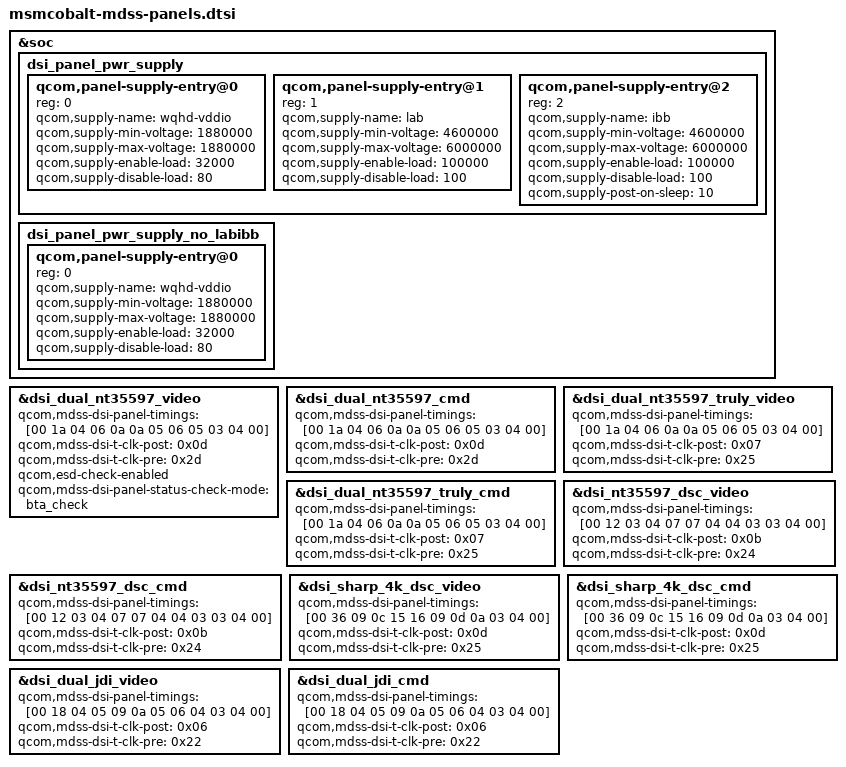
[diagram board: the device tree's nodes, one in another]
/* Copyright (c) 2016, The Linux Foundation. All rights reserved.
 *
 * This program is free software; you can redistribute it and/or modify
 * it under the terms of the GNU General Public License version 2 and
 * only version 2 as published by the Free Software Foundation.
 *
 * This program is distributed in the hope that it will be useful,
 * but WITHOUT ANY WARRANTY; without even the implied warranty of
 * MERCHANTABILITY or FITNESS FOR A PARTICULAR PURPOSE.  See the
 * GNU General Public License for more details.
 */

#include "dsi-panel-sim-video.dtsi"
#include "dsi-panel-sim-dualmipi-video.dtsi"
#include "dsi-panel-nt35597-dualmipi-wqxga-video.dtsi"
#include "dsi-panel-nt35597-dualmipi-wqxga-cmd.dtsi"
#include "dsi-panel-nt35597-truly-dualmipi-wqxga-video.dtsi"
#include "dsi-panel-nt35597-truly-dualmipi-wqxga-cmd.dtsi"
#include "dsi-panel-nt35597-dsc-wqxga-video.dtsi"
#include "dsi-panel-nt35597-dsc-wqxga-cmd.dtsi"
#include "dsi-panel-sharp-dsc-4k-video.dtsi"
#include "dsi-panel-sharp-dsc-4k-cmd.dtsi"
#include "dsi-panel-jdi-dualmipi-video.dtsi"
#include "dsi-panel-jdi-dualmipi-cmd.dtsi"

&soc {
	dsi_panel_pwr_supply: dsi_panel_pwr_supply {
		#address-cells = <1>;
		#size-cells = <0>;

		qcom,panel-supply-entry@0 {
			reg = <0>;
			qcom,supply-name = "wqhd-vddio";
			qcom,supply-min-voltage = <1880000>;
			qcom,supply-max-voltage = <1880000>;
			qcom,supply-enable-load = <32000>;
			qcom,supply-disable-load = <80>;
		};

		qcom,panel-supply-entry@1 {
			reg = <1>;
			qcom,supply-name = "lab";
			qcom,supply-min-voltage = <4600000>;
			qcom,supply-max-voltage = <6000000>;
			qcom,supply-enable-load = <100000>;
			qcom,supply-disable-load = <100>;
		};

		qcom,panel-supply-entry@2 {
			reg = <2>;
			qcom,supply-name = "ibb";
			qcom,supply-min-voltage = <4600000>;
			qcom,supply-max-voltage = <6000000>;
			qcom,supply-enable-load = <100000>;
			qcom,supply-disable-load = <100>;
			qcom,supply-post-on-sleep = <10>;
		};
	};
};

&soc {
	dsi_panel_pwr_supply_no_labibb: dsi_panel_pwr_supply_no_labibb {
		#address-cells = <1>;
		#size-cells = <0>;

		qcom,panel-supply-entry@0 {
			reg = <0>;
			qcom,supply-name = "wqhd-vddio";
			qcom,supply-min-voltage = <1880000>;
			qcom,supply-max-voltage = <1880000>;
			qcom,supply-enable-load = <32000>;
			qcom,supply-disable-load = <80>;
		};
	};
};

&dsi_dual_nt35597_video {
	qcom,mdss-dsi-panel-timings = [00 1a 04 06 0a 0a 05 06 05 03 04 00];
	qcom,mdss-dsi-t-clk-post = <0x0d>;
	qcom,mdss-dsi-t-clk-pre = <0x2d>;
	qcom,esd-check-enabled;
	qcom,mdss-dsi-panel-status-check-mode = "bta_check";
};

&dsi_dual_nt35597_cmd {
	qcom,mdss-dsi-panel-timings = [00 1a 04 06 0a 0a 05 06 05 03 04 00];
	qcom,mdss-dsi-t-clk-post = <0x0d>;
	qcom,mdss-dsi-t-clk-pre = <0x2d>;
};

&dsi_dual_nt35597_truly_video {
	qcom,mdss-dsi-panel-timings = [00 1a 04 06 0a 0a 05 06 05 03 04 00];
	qcom,mdss-dsi-t-clk-post = <0x07>;
	qcom,mdss-dsi-t-clk-pre = <0x25>;
};

&dsi_dual_nt35597_truly_cmd {
	qcom,mdss-dsi-panel-timings = [00 1a 04 06 0a 0a 05 06 05 03 04 00];
	qcom,mdss-dsi-t-clk-post = <0x07>;
	qcom,mdss-dsi-t-clk-pre = <0x25>;
};

&dsi_nt35597_dsc_video {
	qcom,mdss-dsi-panel-timings = [00 12 03 04 07 07 04 04 03 03 04 00];
	qcom,mdss-dsi-t-clk-post = <0x0b>;
	qcom,mdss-dsi-t-clk-pre = <0x24>;
};

&dsi_nt35597_dsc_cmd {
	qcom,mdss-dsi-panel-timings = [00 12 03 04 07 07 04 04 03 03 04 00];
	qcom,mdss-dsi-t-clk-post = <0x0b>;
	qcom,mdss-dsi-t-clk-pre = <0x24>;
};

&dsi_sharp_4k_dsc_video {
	qcom,mdss-dsi-panel-timings = [00 36 09 0c 15 16 09 0d 0a 03 04 00];
	qcom,mdss-dsi-t-clk-post = <0x0d>;
	qcom,mdss-dsi-t-clk-pre = <0x25>;
};

&dsi_sharp_4k_dsc_cmd {
	qcom,mdss-dsi-panel-timings = [00 36 09 0c 15 16 09 0d 0a 03 04 00];
	qcom,mdss-dsi-t-clk-post = <0x0d>;
	qcom,mdss-dsi-t-clk-pre = <0x25>;
};

&dsi_dual_jdi_video {
	qcom,mdss-dsi-panel-timings = [00 18 04 05 09 0a 05 06 04 03 04 00];
	qcom,mdss-dsi-t-clk-post = <0x06>;
	qcom,mdss-dsi-t-clk-pre = <0x22>;
};

&dsi_dual_jdi_cmd {
	qcom,mdss-dsi-panel-timings = [00 18 04 05 09 0a 05 06 04 03 04 00];
	qcom,mdss-dsi-t-clk-post = <0x06>;
	qcom,mdss-dsi-t-clk-pre = <0x22>;
};
